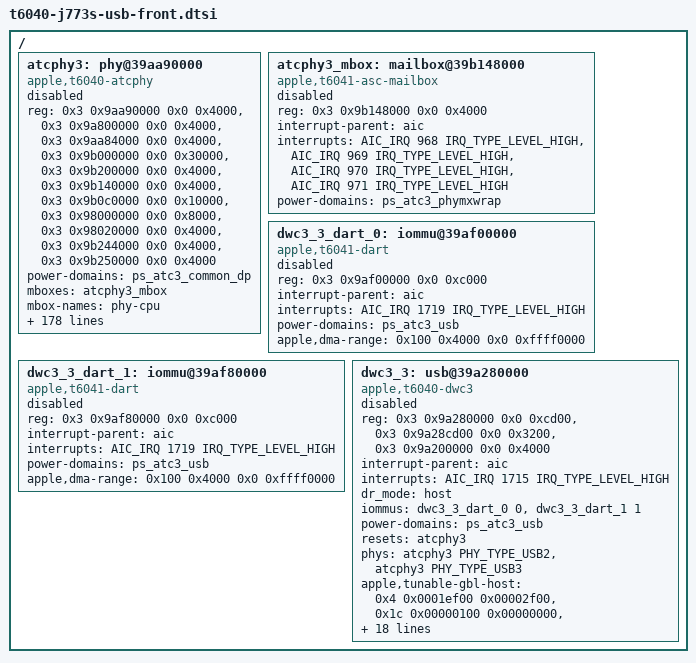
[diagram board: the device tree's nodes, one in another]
// SPDX-License-Identifier: GPL-2.0+ OR MIT
/*
 * The J773s's two front USB-C ports: an on-board USB2/USB3 hub behind ATC3,
 * whose controller (ADT usb-drd3) is a fixed host with no PD controller.
 * The hub's firmware is on its own flash (ADT spi3 usb3hub-flash).
 *
 * Disabled until the T6040 PHY driver has a fixed-host mode: it brings USB3
 * up only for a Type-C plug orientation. Enabling this also takes the ATC3
 * power domains. Tunables are this ADT's atc-phy3 and usb-drd3 tables
 * (macOS 26.6.2); DRD_USB31_GBL_DEFAULT is followed by the GCTL.PWRDNSCALE
 * entry the other ports use.
 */

/ {
	atcphy3: phy@39aa90000 {
		compatible = "apple,t6040-atcphy";
		reg = <0x3 0x9aa90000 0x0 0x4000>,
		      <0x3 0x9a800000 0x0 0x4000>,
		      <0x3 0x9aa84000 0x0 0x4000>,
		      <0x3 0x9b000000 0x0 0x30000>,
		      <0x3 0x9b200000 0x0 0x4000>,
		      <0x3 0x9b140000 0x0 0x4000>,
		      <0x3 0x9b0c0000 0x0 0x10000>,
		      <0x3 0x98000000 0x0 0x8000>,
		      <0x3 0x98020000 0x0 0x4000>,
		      <0x3 0x9b244000 0x0 0x4000>,
		      <0x3 0x9b250000 0x0 0x4000>;
		reg-names = "bank0", "bank1", "pipehandler", "core", "cfg", "cpu",
			    "cpu-data", "axi2af", "axi2af-lioa", "fabric", "common-cfg";
		#phy-cells = <1>;
		#reset-cells = <0>;
		power-domains = <&ps_atc3_common_dp>;
		mboxes = <&atcphy3_mbox>;
		mbox-names = "phy-cpu";
		nonposted-mmio;

		apple,tunable-axi2af =
			<0x0 0x800000ff 0x80000025>,
			<0x4 0x80ff00ff 0x80250003>,
			<0x8 0x80ff00ff 0x80250003>,
			<0xc 0x80ff00ff 0x80250005>,
			<0x10 0x80ff00ff 0x80250003>,
			<0x14 0x80ff00ff 0x80250003>,
			<0x18 0x80ff00ff 0x80250003>,
			<0x1c 0x80ff00ff 0x80250003>,
			<0x20 0x800000ff 0x8000001e>,
			<0x24 0x800000ff 0x8000004a>,
			<0x28 0x80ff00ff 0x804a0006>,
			<0x2c 0x80ff00ff 0x804a0006>,
			<0x30 0x80ff00ff 0x804a0006>,
			<0x34 0x80ff00ff 0x804a0006>,
			<0x38 0x80ff00ff 0x804a0006>,
			<0x3c 0x80ff00ff 0x804a0006>,
			<0x40 0x800000ff 0x8000001e>,
			<0x44 0x800000ff 0x8000001e>,
			<0x48 0x800000ff 0x8000001e>,
			<0x100 0x000000ff 0x000000ff>,
			<0x108 0xffff0006 0x00100000>,
			<0x304 0x3f3f0000 0x04040000>,
			<0x308 0x000fffff 0x00001681>,
			<0x30c 0x000fffff 0x00001680>,
			<0x310 0x70000fff 0x000001e0>,
			<0x314 0xf0000fff 0x800001e0>,
			<0x318 0x70000fff 0x000001e0>,
			<0x31c 0xf0000fff 0x800001e0>,
			<0x320 0x70000fff 0x000005a0>,
			<0x324 0xf0000fff 0x800005a0>,
			<0x328 0x70000fff 0x000005a0>,
			<0x32c 0xf0000fff 0x800005a0>,
			<0x330 0x70000fff 0x000005a0>,
			<0x334 0xf0000fff 0x800005a0>,
			<0x338 0x70000fff 0x000005a0>,
			<0x33c 0x70000fff 0x000005a0>,
			<0x340 0x70000fff 0x000005a0>,
			<0x344 0x70000fff 0x000005a0>,
			<0x348 0x70000fff 0x000005a0>,
			<0x34c 0x70000fff 0x000005a0>,
			<0x350 0x70000fff 0x000005a0>,
			<0x358 0xffffffff 0x0000ffff>,
			<0x35c 0xffffffff 0x0000ffff>,
			<0x408 0xffff0020 0x00210020>,
			<0x40c 0x000fffff 0x00001681>,
			<0x410 0x000fffff 0x00001680>,
			<0x414 0x70000fff 0x000001e0>,
			<0x418 0x70000fff 0x000001e0>,
			<0x41c 0x70000fff 0x000001e0>,
			<0x420 0x70000fff 0x000001e0>,
			<0x424 0x70000fff 0x000005a0>,
			<0x428 0x70000fff 0x000005a0>,
			<0x42c 0x70000fff 0x000005a0>,
			<0x430 0x70000fff 0x000005a0>,
			<0x434 0x70000fff 0x000005a0>,
			<0x438 0x70000fff 0x000005a0>,
			<0x43c 0x70000fff 0x000005a0>,
			<0x440 0x70000fff 0x000005a0>,
			<0x444 0x70000fff 0x000005a0>,
			<0x448 0x70000fff 0x000005a0>,
			<0x44c 0x70000fff 0x000005a0>,
			<0x450 0x70000fff 0x000005a0>,
			<0x454 0x70000fff 0x000005a0>,
			<0x948 0x07ff07ff 0x00280000>,
			<0xa48 0x07ff07ff 0x00400040>,
			<0xb48 0x07ff07ff 0x00b8010e>,
			<0xc48 0x07ff07ff 0x00400020>,
			<0xd48 0x07ff07ff 0x008a008a>,
			<0x1000 0xffffffff 0x7fffffff>,
			<0x4008 0x00000001 0x00000001>,
			<0x400c 0x00000001 0x00000001>,
			<0x4014 0x00000001 0x00000001>,
			<0x4018 0x00000001 0x00000000>,
			<0x401c 0x00000001 0x00000001>;
		apple,tunable-axi2af-lioa =
			<0x28 0x0000fe2f 0x00000000>,
			<0x2c 0x00000007 0x00000000>,
			<0x30 0x0000007f 0x00000000>,
			<0x34 0x000000ff 0x00000000>,
			<0x58 0x0000010b 0x00000000>;
		apple,tunable-fabric =
			<0x4 0x003f003f 0x00200020>,
			<0xc 0x000000f1 0x000000a1>,
			<0x10 0x0000801f 0x00000004>,
			<0x18 0x003f003f 0x00200020>,
			<0x20 0x000000f1 0x000000a1>,
			<0x24 0x0000801f 0x00000004>,
			<0x2c 0x00ff00ff 0x00960096>,
			<0x34 0x000000f1 0x00000071>,
			<0x38 0x0000801f 0x00000004>,
			<0x40 0x0000003f 0x00000020>,
			<0x48 0x0000801f 0x00000004>,
			<0x50 0x007f007f 0x00450045>,
			<0x58 0x0000801f 0x00000004>,
			<0x60 0x0000003f 0x00000020>,
			<0x68 0x0000801f 0x00000004>,
			<0x70 0x00000001 0x00000001>,
			<0x74 0x0000801f 0x00000004>,
			<0x7c 0x007f007f 0x00400040>,
			<0x80 0x000000f1 0x00000011>,
			<0x84 0x00000001 0x00000001>,
			<0x88 0x00000001 0x00000001>,
			<0x8c 0x0000801f 0x00000004>,
			<0x94 0x001f001f 0x00100010>,
			<0x98 0x000000f1 0x00000011>,
			<0x9c 0x0000801f 0x00000004>,
			<0xa4 0x000000ff 0x000000e0>,
			<0xa8 0x0000801f 0x00000004>,
			<0xb0 0x0000003f 0x00000020>,
			<0xb8 0x0000801f 0x00000004>,
			<0xc0 0x0000003f 0x00000020>,
			<0xc8 0x0000801f 0x00000004>,
			<0xd0 0x001f001f 0x00100010>,
			<0xd8 0x00000001 0x00000001>,
			<0xdc 0x00000001 0x00000001>,
			<0xe0 0x0000801f 0x00000004>,
			<0xe8 0x0000000f 0x00000008>,
			<0xec 0x0000801f 0x00000004>,
			<0xf4 0xffffffff 0x01010101>,
			<0xf8 0x0000801f 0x00000004>,
			<0x100 0x00000001 0x00000001>,
			<0x104 0x00000001 0x00000001>,
			<0x108 0x0000801f 0x00000004>,
			<0x110 0x0000801f 0x00000004>,
			<0x118 0x0000801f 0x00000004>,
			<0x120 0x00000001 0x00000001>,
			<0x124 0x00000001 0x00000001>,
			<0x128 0x0000801f 0x00000004>,
			<0x130 0xffffffff 0x01010101>,
			<0x134 0x0000801f 0x00000004>,
			<0x13c 0x00000001 0x00000001>,
			<0x140 0x00000001 0x00000001>,
			<0x144 0x0000801f 0x00000004>,
			<0x14c 0x00000001 0x00000001>,
			<0x150 0x00000001 0x00000001>,
			<0x154 0x0000801f 0x00000004>,
			<0x15c 0x0000801f 0x00000004>,
			<0x164 0xffffffff 0x01010101>,
			<0x168 0x0000ffff 0x00000101>,
			<0x16c 0x0000801f 0x00000004>,
			<0x174 0x00000001 0x00000001>,
			<0x178 0x00000001 0x00000001>,
			<0x17c 0x0000801f 0x00000004>,
			<0x184 0x00000001 0x00000001>,
			<0x188 0x00000001 0x00000001>,
			<0x18c 0x0000801f 0x00000004>;
		apple,tunable-common-cfg =
			<0x8 0x00000001 0x00000001>;
		apple,tunable-lane0 =
			<0xd094 0x00080000 0x00080000>,
			<0xd098 0x00080000 0x00080000>,
			<0xd0a4 0x00800000 0x00800000>,
			<0xd0a8 0x00200000 0x00200000>;
		apple,tunable-lane1 =
			<0x1d094 0x00080000 0x00080000>,
			<0x1d098 0x00080000 0x00080000>,
			<0x1d0a4 0x00800000 0x00800000>,
			<0x1d0a8 0x00200000 0x00200000>;
		apple,tunable-aus40cmn-shm =
			<0xa04 0x0000007c 0x00000050>;
		apple,tunable-auspll =
			<0x3224 0x00000c00 0x00000800>,
			<0x3230 0x0000001f 0x0000000f>,
			<0x3240 0x07d8007f 0x04000049>,
			<0x32b0 0x0b800000 0x01800000>,
			<0x32e8 0x00060001 0x00040001>,
			<0x3338 0x0f800000 0x07800000>;
		apple,tunable-cio4pll =
			<0x3a30 0x0000001f 0x0000000f>,
			<0x3a4c 0x0000fe7f 0x00004e1d>,
			<0x3ab0 0x00700000 0x00300000>,
			<0x3ae8 0x00060000 0x00020000>;
		apple,tunable-pipehandler =
			<0x44 0x00000004 0x00000004>;
		apple,tunable-usb2-host =
			<0x8 0x00007003 0x00000003>;
		status = "disabled";
	};

	atcphy3_mbox: mailbox@39b148000 {
		compatible = "apple,t6041-asc-mailbox", "apple,asc-mailbox-v4";
		reg = <0x3 0x9b148000 0x0 0x4000>;
		interrupt-parent = <&aic>;
		interrupts = <AIC_IRQ 968 IRQ_TYPE_LEVEL_HIGH>,
			     <AIC_IRQ 969 IRQ_TYPE_LEVEL_HIGH>,
			     <AIC_IRQ 970 IRQ_TYPE_LEVEL_HIGH>,
			     <AIC_IRQ 971 IRQ_TYPE_LEVEL_HIGH>;
		interrupt-names = "send-empty", "send-not-empty",
				  "recv-empty", "recv-not-empty";
		#mbox-cells = <0>;
		power-domains = <&ps_atc3_phymxwrap>;
		status = "disabled";
	};

	dwc3_3_dart_0: iommu@39af00000 {
		compatible = "apple,t6041-dart", "apple,t8110-dart";
		reg = <0x3 0x9af00000 0x0 0xc000>;
		interrupt-parent = <&aic>;
		interrupts = <AIC_IRQ 1719 IRQ_TYPE_LEVEL_HIGH>;
		power-domains = <&ps_atc3_usb>;
		#iommu-cells = <1>;
		apple,dma-range = <0x100 0x4000 0x0 0xffff0000>;
		status = "disabled";
	};

	dwc3_3_dart_1: iommu@39af80000 {
		compatible = "apple,t6041-dart", "apple,t8110-dart";
		reg = <0x3 0x9af80000 0x0 0xc000>;
		interrupt-parent = <&aic>;
		interrupts = <AIC_IRQ 1719 IRQ_TYPE_LEVEL_HIGH>;
		power-domains = <&ps_atc3_usb>;
		#iommu-cells = <1>;
		apple,dma-range = <0x100 0x4000 0x0 0xffff0000>;
		status = "disabled";
	};

	dwc3_3: usb@39a280000 {
		compatible = "apple,t6040-dwc3", "apple,t8103-dwc3";
		reg = <0x3 0x9a280000 0x0 0xcd00>,
		      <0x3 0x9a28cd00 0x0 0x3200>,
		      <0x3 0x9a200000 0x0 0x4000>;
		reg-names = "dwc3-core", "dwc3-apple", "drd-cfg";
		interrupt-parent = <&aic>;
		interrupts = <AIC_IRQ 1715 IRQ_TYPE_LEVEL_HIGH>;
		dr_mode = "host";
		iommus = <&dwc3_3_dart_0 0>, <&dwc3_3_dart_1 1>;
		power-domains = <&ps_atc3_usb>;
		resets = <&atcphy3>;
		phys = <&atcphy3 PHY_TYPE_USB2>, <&atcphy3 PHY_TYPE_USB3>;
		phy-names = "usb2-phy", "usb3-phy";

		apple,tunable-gbl-host =
			<0x4 0x0001ef00 0x00002f00>,
			<0x1c 0x00000100 0x00000000>,
			<0x2c 0x000a07ff 0x000800c8>,
			<0x100 0x02000100 0x02000100>,
			<0x504 0x00001000 0x00000000>,
			<0x528 0xff0000ff 0x06000006>,
			<0x52c 0xff0000ff 0x08000008>,
			<0x538 0x00000800 0x00000800>,
			<0x580 0xffffffff 0x6f000006>;
		apple,tunable-dbg =
			<0x0 0x00000008 0x00000008>;
		apple,tunable-cfg-host =
			<0x20 0x000000ff 0x0000001b>;
		apple,tunable-link =
			<0x20 0x7ff00000 0x4e900000>,
			<0x24 0x001f8000 0x000b8000>,
			<0x60 0x0003ffff 0x00000600>,
			<0x60 0x0003ffff 0x00008fc7>;
		apple,tunable-gbl-default =
			<0x64 0x00000002 0x00000000>,
			<0x10 0xfff80000 0x00680000>;
		status = "disabled";
	};
};
